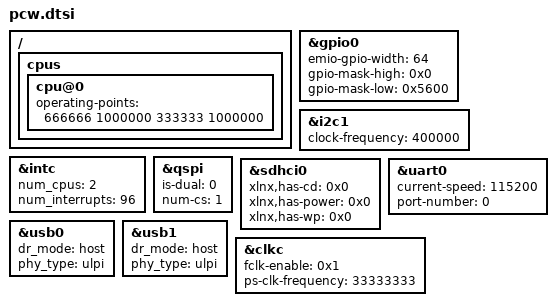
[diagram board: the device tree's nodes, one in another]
/*
 * CAUTION: This file is automatically generated by Xilinx.
 * Version: HSI 2016.3
 * Today is: Sun Oct 22 23:49:29 2017
*/


/ {
	cpus {
		cpu@0 {
			operating-points = <666666 1000000 333333 1000000>;
		};
	};
};
&gpio0 {
	emio-gpio-width = <64>;
	gpio-mask-high = <0x0>;
	gpio-mask-low = <0x5600>;
};
&i2c1 {
	clock-frequency = <400000>;
	status = "okay";
};
&intc {
	num_cpus = <2>;
	num_interrupts = <96>;
};
&qspi {
	is-dual = <0>;
	num-cs = <1>;
	status = "okay";
};
&sdhci0 {
	status = "okay";
	xlnx,has-cd = <0x0>;
	xlnx,has-power = <0x0>;
	xlnx,has-wp = <0x0>;
};
&uart0 {
	current-speed = <115200>;
	device_type = "serial";
	port-number = <0>;
	status = "okay";
};
&usb0 {
	dr_mode = "host";
	phy_type = "ulpi";
	status = "okay";
};
&usb1 {
	dr_mode = "host";
	phy_type = "ulpi";
	status = "okay";
};
&clkc {
	fclk-enable = <0x1>;
	ps-clk-frequency = <33333333>;
};
